# CONTROLSS_OUTPUTXBAR_CONTROLSS_502D8000h register map
Vendor: Texas Instruments
Peripheral module from a debugger description file (folder AM261x).
Registers are 32-bit, read-write, reset 0x0 unless marked. A register's access mark holds for its fields unless they carry their own. Offsets are as the file gives them; lines under a group give offsets from that group; [hi:lo] are bit positions; {n}, {i} and the like mark numbered series; 'fields as' and 'values as' point back to an identical list; <NAME> marks a mode.

## CONTROLSS
0x10 CONTROLSS_OUTPUTXBAR_STATUS ro
  [15:0] OUTPUTXBAR_STATUS_STS — Status
0x14 CONTROLSS_OUTPUTXBAR_FLAGINVERT
  [15:0] OUTPUTXBAR_FLAGINVERT_INVERT — FlagInvert
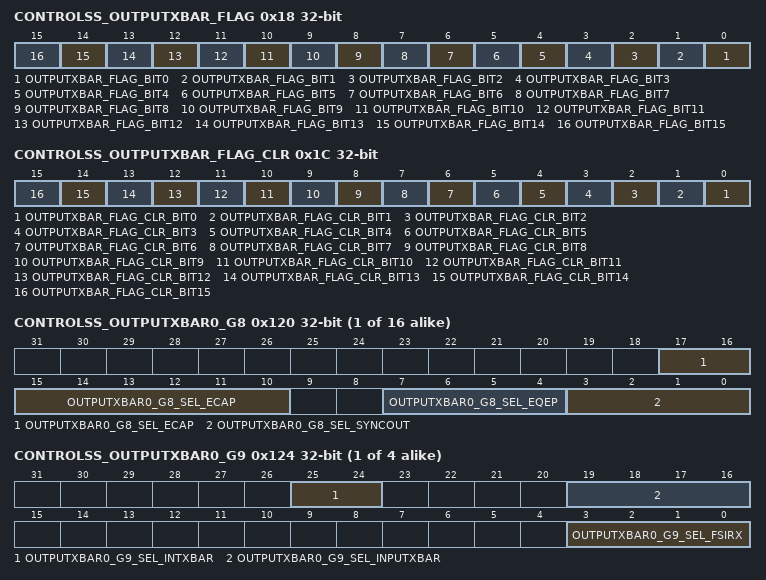
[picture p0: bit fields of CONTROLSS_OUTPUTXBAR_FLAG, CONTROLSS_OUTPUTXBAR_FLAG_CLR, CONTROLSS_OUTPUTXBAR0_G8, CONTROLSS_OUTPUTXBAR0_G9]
0x18 CONTROLSS_OUTPUTXBAR_FLAG
  [n] OUTPUTXBAR_FLAG_BIT{n} (n=0..15) — Output XBAR flag
0x1C CONTROLSS_OUTPUTXBAR_FLAG_CLR
  [n] OUTPUTXBAR_FLAG_CLR_BIT{n} (n=0..15) — Output XBAR flag clear
0x20 CONTROLSS_OUTPUTXBAR_FLAGFORCE
  [15:0] OUTPUTXBAR_FLAGFORCE_FRC — FlagForce
0x24 CONTROLSS_OUTPUTXBAR_OUTLATCH
  [15:0] OUTPUTXBAR_OUTLATCH_LATCHSEL — OutLatch
0x28 CONTROLSS_OUTPUTXBAR_OUTSTRETCH
  [15:0] OUTPUTXBAR_OUTSTRETCH_STRETCHSEL — OutStretch
0x2C CONTROLSS_OUTPUTXBAR_OUTLENGTH
  [15:0] OUTPUTXBAR_OUTLENGTH_LENGTHSEL — OutLength
0x30 CONTROLSS_OUTPUTXBAR_OUTINVERT
  [15:0] OUTPUTXBAR_OUTINVERT_OUTINVERT — OutInvert
{0x100+0x40*i} CONTROLSS_OUTPUTXBAR{i}_G0 (i=0..15)
  [9:0] OUTPUTXBAR{i}_G0_SEL — G0: PWM XBAR{i} G0 input bit select. Input source is PWM[x].TRIPOUT1:PWM[x] TRIPOUT selected0:PWM[x] TRIPOUT is de-selected
{0x104+0x40*i} CONTROLSS_OUTPUTXBAR{i}_G1 (i=0..15)
  [9:0] OUTPUTXBAR{i}_G1_SEL — G1: OUTPUT XBAR{i} G1 input bit select. Input source is PWM[x].SOCA1:PWM[x] SOCA selected0:PWM[x] SOCA is de-selected
{0x108+0x40*i} CONTROLSS_OUTPUTXBAR{i}_G2 (i=0..15)
  [9:0] OUTPUTXBAR{i}_G2_SEL — G2: OUTPUT XBAR{i} G2 input bit select. Input source is PWM[x].SOCB1:PWM[x] SOCB selected0:PWM[x] SOCB is de-selected
{0x10C+0x40*i} CONTROLSS_OUTPUTXBAR{i}_G3 (i=0..15)
  [9:0] OUTPUTXBAR{i}_G3_SEL — G3: OUTPUT XBAR{i} G3 input bit select. Input source is DEL[x].ACTIVE1:DEL[x] ACTIVE selected0:DEL[x] ACTIVE is de-selected
{0x110+0x40*i} CONTROLSS_OUTPUTXBAR{i}_G4 (i=0..15)
  [9:0] OUTPUTXBAR{i}_G4_SEL — G4: OUTPUT XBAR{i} G4 input bit select. Input source is DEL[x].TRIP1:DEL[x] TRIP selected0:DEL[x] TRIP is de-selected
{0x114+0x40*i} CONTROLSS_OUTPUTXBAR{i}_G5 (i=0..15)
  [23:0] OUTPUTXBAR{i}_G5_SEL — G5: OUTPUT XBAR{i} G5 input bit select.0:SDFM0.FILT1CEVT11:SDFM0.FILT1CEVT22:SDFM0.FILT1COMPHZ3:SDFM0.FILT2CEVT14:SDFM0.FILT2CEVT25:SDFM0.FILT2COMPHZ6:SDFM0.FILT3CEVT17:SDFM0.FILT3CEVT28:SDFM0.FILT3COMPHZ9:SDFM0.FILT4CEVT110:SDFM0.FILT4CEVT211:SDFM0.FILT4COMPHZ12:SDFM1.FILT1CEVT113:SDFM1.FILT1CEVT214:SDFM1.FILT1COMPHZ15:SDFM1.FILT2CEVT116:SDFM1.FILT2CEVT217:SDFM1.FILT2COMPHZ18:SDFM1.FILT3CEVT119:SDFM1.FILT3CEVT220:SDFM1.FILT3COMPHZ21:SDFM1.FILT4CEVT122:SDFM1.FILT4CEVT223:SDFM1.FILT4COMPHZ
{0x118+0x40*i} CONTROLSS_OUTPUTXBAR{i}_G6 (i=0..15)
  [17:0] OUTPUTXBAR{i}_G6_SEL — G6: OUTPUT XBAR{i} G6 Input Select0:CMP12SS0.CTRIPOUTL1:CMP12SS0.CTRIPOUTH2:CMP12SS1.CTRIPOUTL3:CMP12SS1.CTRIPOUTH4:CMP12SS2.CTRIPOUTL5:CMP12SS2.CTRIPOUTH6:CMP12SS3.CTRIPOUTL7:CMP12SS3.CTRIPOUTH8:CMP12SS4.CTRIPOUTL9:CMP12SS4.CTRIPOUTH10:CMP12SS5.CTRIPOUTL11:CMP12SS5.CTRIPOUTH12:CMP12SS6.CTRIPOUTL13:CMP12SS6.CTRIPOUTH14:CMP12SS7.CTRIPOUTL15:CMP12SS7.CTRIPOUTH16:CMP12SS8.CTRIPOUTL17:CMP12SS8.CTRIPOUTH
{0x11C+0x40*i} CONTROLSS_OUTPUTXBAR{i}_G7 (i=0..15)
  [11:0] OUTPUTXBAR{i}_G7_SEL — G7: OUTPUT XBAR{i} G7 Input Select0:ADC0.EVT11:ADC0.EVT22:ADC0.EVT33:ADC0.EVT44:ADC1.EVT15:ADC1.EVT26:ADC1.EVT37:ADC1 EVT48:ADC2.EVT19:ADC2 EVT210:ADC2.EVT311:ADC2.EVT4
{0x120+0x40*i} CONTROLSS_OUTPUTXBAR{i}_G8 (i=0..15)
  [17:10] OUTPUTXBAR{i}_G8_SEL_ECAP — G8: OUTPUT XBAR{i} G8 Input Select1710:ECAP.OUT[7:0]
  [7:4] OUTPUTXBAR{i}_G8_SEL_EQEP — G8: OUTPUT XBAR{i} G8 Input Select4:EQEP0.I_OUT5:EQEP0.S_OUT6:EQEP1.I_OUT7:EQEP1.S_OUT
  [3:0] OUTPUTXBAR{i}_G8_SEL_SYNCOUT — G8: OUTPUT XBAR{i} G8 Input Select0:PWMSyncOutXBAR.SYNCOUT01:PWMSyncOutXBAR.SYNCOUT12:PWMSyncOutXBAR.SYNCOUT23:PWMSyncOutXBAR.SYNCOUT3
{0x124+0x40*i} CONTROLSS_OUTPUTXBAR{i}_G9 (i=0..3)
  [25:24] OUTPUTXBAR{i}_G9_SEL_INTXBAR — G9: OUTPUT XBAR{i} G9 Input Select24:INTXBAR.OUT725:INTXBAR.OUT15
  [19:16] OUTPUTXBAR{i}_G9_SEL_INPUTXBAR — G9: OUTPUT XBAR{i} G9 Input Select16:INPUTXBAR.OUT717:INPUTXBAR.OUT1518:INPUTXBAR.OUT2319:INPUTXBAR.OUT31
  [3:0] OUTPUTXBAR{i}_G9_SEL_FSIRX — G9: OUTPUT XBAR{i} G9 Input Select0:FSIRX0.RX_TRIG01:FSIRX0.RX_TRIG12:FSIRX0.RX_TRIG23:FSIRX0.RX_TRIG3
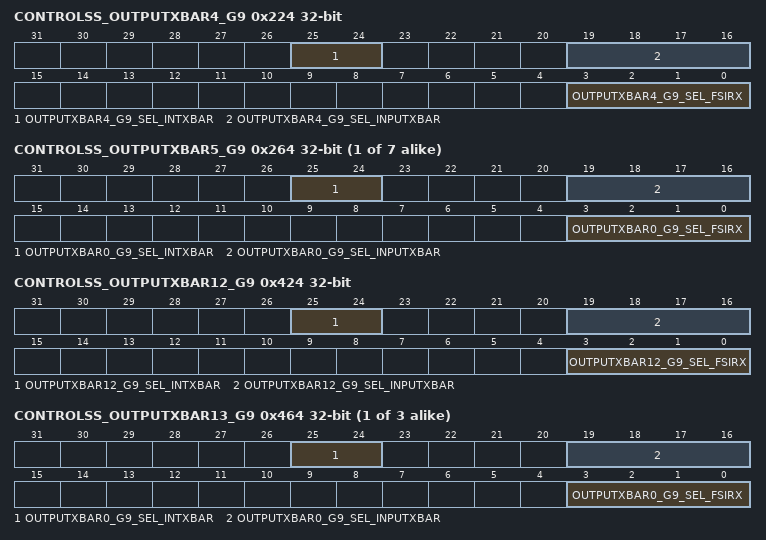
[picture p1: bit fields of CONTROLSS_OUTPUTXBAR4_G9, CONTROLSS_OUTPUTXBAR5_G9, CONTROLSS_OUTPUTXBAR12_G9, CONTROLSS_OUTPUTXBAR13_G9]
0x224 CONTROLSS_OUTPUTXBAR4_G9
  [25:24] OUTPUTXBAR4_G9_SEL_INTXBAR — G9: OUTPUT XBAR5 G9 Input Select24:INTXBAR.OUT725:INTXBAR.OUT15
  [19:16] OUTPUTXBAR4_G9_SEL_INPUTXBAR — G9: OUTPUT XBAR5 G9 Input Select16:INPUTXBAR.OUT717:INPUTXBAR.OUT1518:INPUTXBAR.OUT2319:INPUTXBAR.OUT31
  [3:0] OUTPUTXBAR4_G9_SEL_FSIRX — G9: OUTPUT XBAR5 G9 Input Select0:FSIRX0.RX_TRIG01:FSIRX0.RX_TRIG12:FSIRX0.RX_TRIG23:FSIRX0.RX_TRIG3
{0x124+0x40*i} CONTROLSS_OUTPUTXBAR{i}_G9 (i=5..11)
  fields as CONTROLSS_OUTPUTXBAR0_G9
0x424 CONTROLSS_OUTPUTXBAR12_G9
  [25:24] OUTPUTXBAR12_G9_SEL_INTXBAR — G9: OUTPUT XBAR5 G9 Input Select24:INTXBAR.OUT725:INTXBAR.OUT15
  [19:16] OUTPUTXBAR12_G9_SEL_INPUTXBAR — G9: OUTPUT XBAR5 G9 Input Select16:INPUTXBAR.OUT717:INPUTXBAR.OUT1518:INPUTXBAR.OUT2319:INPUTXBAR.OUT31
  [3:0] OUTPUTXBAR12_G9_SEL_FSIRX — G9: OUTPUT XBAR5 G9 Input Select0:FSIRX0.RX_TRIG01:FSIRX0.RX_TRIG12:FSIRX0.RX_TRIG23:FSIRX0.RX_TRIG3
{0x124+0x40*i} CONTROLSS_OUTPUTXBAR{i}_G9 (i=13..15)
  fields as CONTROLSS_OUTPUTXBAR0_G9
